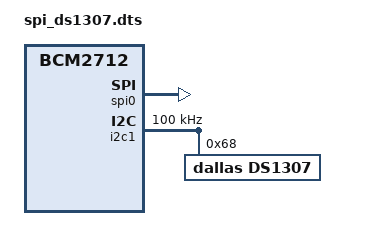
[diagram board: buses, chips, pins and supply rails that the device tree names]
/dts-v1/;
/plugin/;

/ {
	/*
	This is spi0-0cs-overlay.dts (from here: https://github.com/raspberrypi/linux/blob/rpi-6.1.y/arch/arm/boot/dts/overlays/spi0-0cs-overlay.dts )
	merged with the overlay for the DS1307 RTC (based on https://github.com/raspberrypi/linux/blob/rpi-6.1.y/arch/arm/boot/dts/overlays/i2c-rtc-common.dtsi ).
	Also the file is marked as compatible with any Raspberry Pi.
	*/
	compatible = "brcm,bcm2835", "brcm,bcm2836", "brcm,bcm2708", "brcm,bcm2709", "brcm,bcm2712";

	fragment@0 {
		target = <&spi0_cs_pins>;
		frag0: __overlay__ {
			brcm,pins;
		};
	};

	fragment@1 {
		target = <&spi0>;
		__overlay__ {
			cs-gpios;
			status = "okay";
		};
	};

	fragment@2 {
		target = <&spidev1>;
		__overlay__ {
			status = "disabled";
		};
	};

	fragment@3 {
		target = <&spi0_pins>;
		__dormant__ {
			brcm,pins = <10 11>;
		};
	};

	fragment@4 {
		target = <&i2c1>;
		__overlay__ {
			#address-cells = <1>; /* needed to avoid dtc warning */
			#size-cells = <0>; /* needed to avoid dtc warning */
			clock-frequency = <100000>;
			status = "okay";

			ds1307@68 {
				compatible = "dallas,ds1307";
				reg = <0x68>;
				status = "okay";
			};
		};
	};

	__overrides__ {
		no_miso = <0>,"=3";
	};
};
